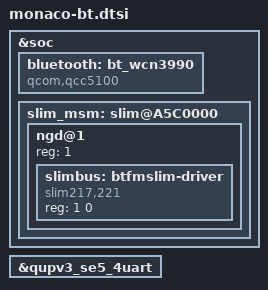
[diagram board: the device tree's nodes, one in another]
#include <dt-bindings/interconnect/qcom,monaco.h>
#include <dt-bindings/soc/qcom,ipcc.h>

&soc {
	bluetooth: bt_wcn3990 {
		compatible = "qcom,qcc5100";

		status = "ok";
	};
	slim_msm: slim@A5C0000 {
		status =  "ok";
		ngd@1 {
			reg = <1>;
			#address-cells = <1>;
			#size-cells = <1>;
			//slimbus child nodes
			slimbus: btfmslim-driver {
					compatible = "slim217,221";
					reg = <1 0>;
			};
		};
	};
};

&qupv3_se5_4uart {
	status = "ok";
};
